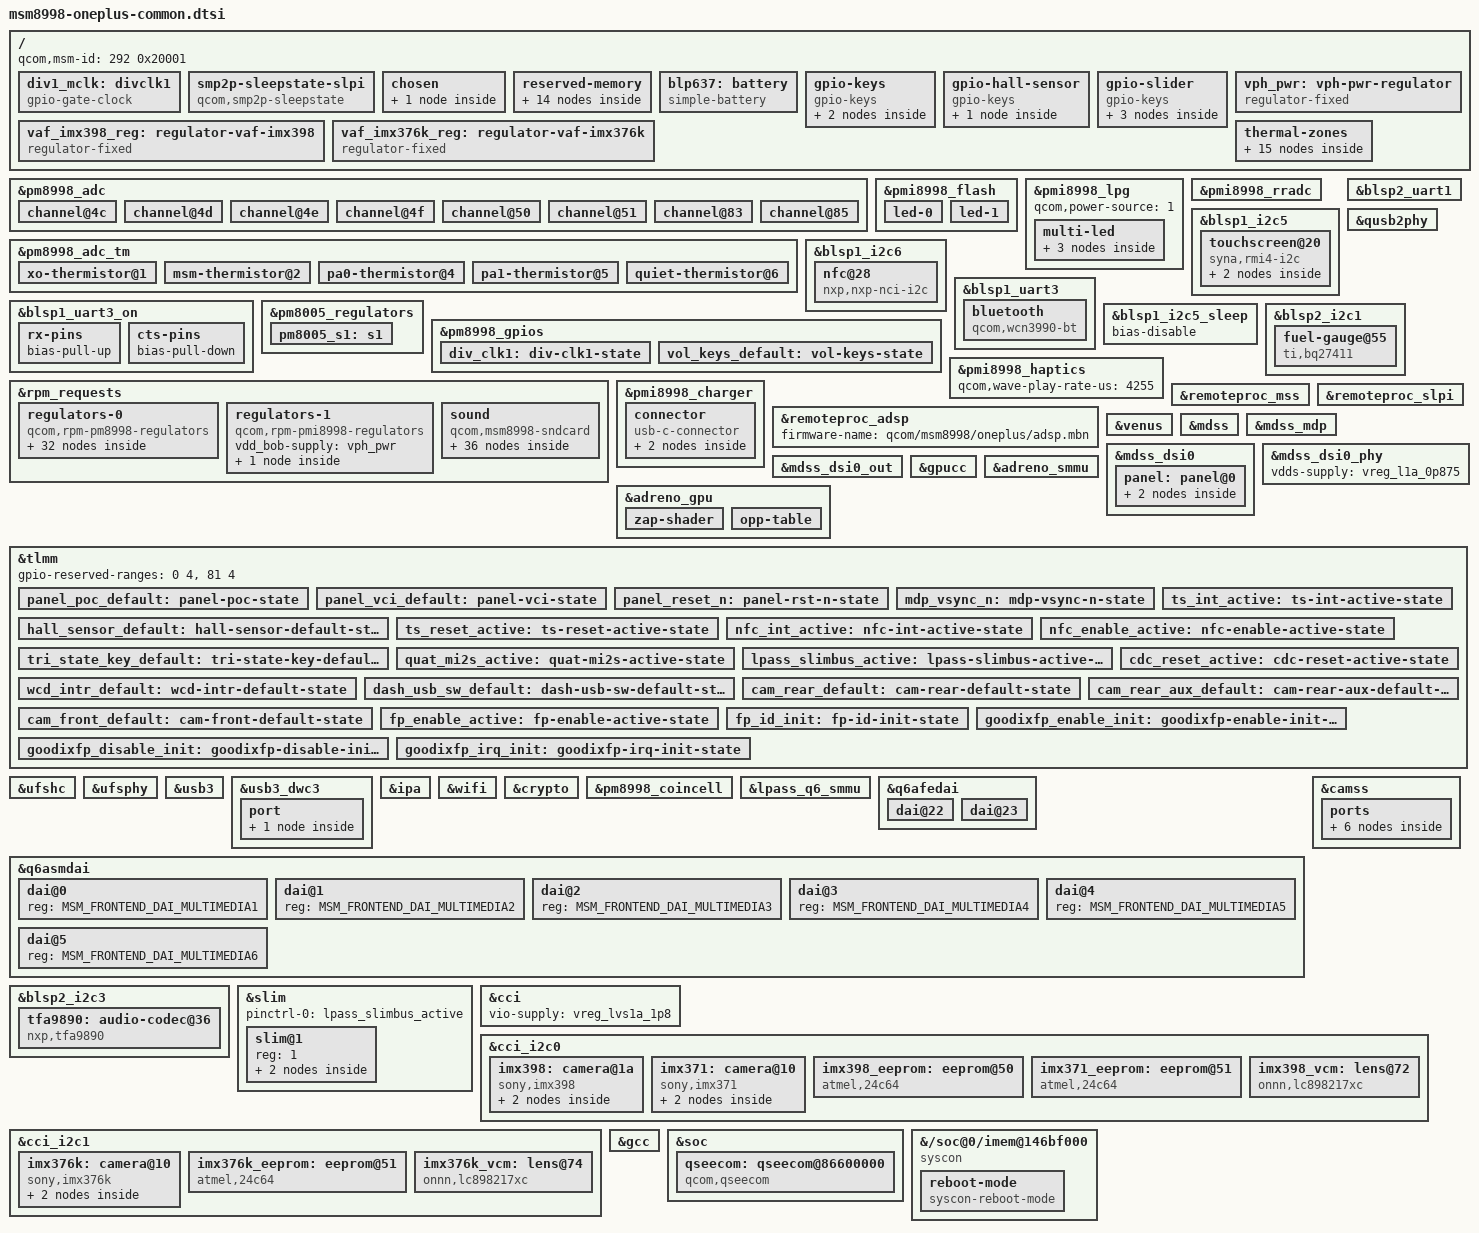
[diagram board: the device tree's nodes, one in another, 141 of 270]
// SPDX-License-Identifier: BSD-3-Clause
/*
 * OnePlus 5(T) (cheeseburger / dumpling) common device tree source based on msm8998-mtp.dtsi
 *
 * Copyright (c) 2021, Jami Kettunen <jamipkettunen@gmail.com>
 * Copyright (c) 2016, The Linux Foundation. All rights reserved.
 */

/dts-v1/;

#include <dt-bindings/gpio/gpio.h>
#include <dt-bindings/iio/qcom,spmi-vadc.h>
#include <dt-bindings/input/linux-event-codes.h>
#include <dt-bindings/leds/common.h>
#include <dt-bindings/pinctrl/qcom,pmic-gpio.h>
#include <dt-bindings/sound/qcom,q6afe.h>
#include <dt-bindings/sound/qcom,q6asm.h>
#include <dt-bindings/sound/qcom,wcd9335.h>
#include <dt-bindings/thermal/thermal.h>
#include "msm8998.dtsi"
#include "pm8005.dtsi"
#include "pm8998.dtsi"
#include "pmi8998.dtsi"

/*
 * Delete following upstream (msm8998.dtsi) reserved
 * memory mappings which are different in this device.
 */
/delete-node/ &adsp_mem;
/delete-node/ &mpss_mem;
/delete-node/ &venus_mem;
/delete-node/ &mba_mem;
/delete-node/ &slpi_mem;
/delete-node/ &ipa_fw_mem;
/delete-node/ &ipa_gsi_mem;
/delete-node/ &gpu_mem;
/delete-node/ &wlan_msa_mem;

/ {
	/* Required for bootloader to select correct board */
	qcom,msm-id = <292 0x20001>; /* 8998 v2.1 */

	div1_mclk: divclk1 {
		compatible = "gpio-gate-clock";
		pinctrl-names = "default";
		pinctrl-0 = <&div_clk1>;
		clocks = <&rpmcc RPM_SMD_DIV_CLK1>;
		#clock-cells = <0>;
		enable-gpios = <&pm8998_gpios 13 GPIO_ACTIVE_HIGH>;
	};

	smp2p-sleepstate-slpi {
		compatible = "qcom,smp2p-sleepstate";
		qcom,smem-states = <&slpi_smp2p_sleepstate 12>;
		qcom,smem-state-names = "sleepstate";
	};

	chosen {
		#address-cells = <2>;
		#size-cells = <2>;
		ranges;

		/* Use display framebuffer setup by the UEFI XBL bootloader for simplefb */
		framebuffer0: framebuffer@9d400000 {
			compatible = "simple-framebuffer";
			reg = <0x0 0x9d400000 0x0 0x2400000>;
			width = <1080>;
			height = <1920>;
			stride = <(1080 * 4)>;
			format = "a8r8g8b8";
			/*
			* That's a lot of clocks, but it's necessary due
			* to unused clk cleanup & no panel driver yet..
			*/
			clocks = <&mmcc MDSS_AHB_CLK>,
				 <&mmcc MDSS_AXI_CLK>,
				 <&mmcc MDSS_VSYNC_CLK>,
				 <&mmcc MDSS_MDP_CLK>,
				 <&mmcc MDSS_BYTE0_CLK>,
				 <&mmcc MDSS_BYTE0_INTF_CLK>,
				 <&mmcc MDSS_PCLK0_CLK>,
				 <&mmcc MDSS_ESC0_CLK>;
			power-domains = <&mmcc MDSS_GDSC>;
			status = "disabled";
		};
	};

	reserved-memory {
		/*
		 * OnePlus ADSP firmware requires 30 MiB in total, so increase the adsp_mem
		 * region by 4 MiB to account for this while relocating the other now
		 * conflicting memory nodes accordingly.
		 */
		adsp_mem: memory@8b200000 {
			reg = <0x0 0x8b200000 0x0 0x1e00000>;
			no-map;
		};

		mpss_mem: memory@8d000000 {
			reg = <0x0 0x8d000000 0x0 0x7000000>;
			no-map;
		};

		venus_mem: memory@94000000 {
			reg = <0x0 0x94000000 0x0 0x500000>;
			no-map;
		};

		mba_mem: memory@94500000 {
			reg = <0x0 0x94500000 0x0 0x200000>;
			no-map;
		};

		slpi_mem: memory@94700000 {
			reg = <0x0 0x94700000 0x0 0xf00000>;
			no-map;
		};

		ipa_fw_mem: memory@95600000 {
			reg = <0x0 0x95600000 0x0 0x10000>;
			no-map;
		};

		ipa_gsi_mem: memory@95610000 {
			reg = <0x0 0x95610000 0x0 0x5000>;
			no-map;
		};

		gpu_mem: memory@95615000 {
			reg = <0x0 0x95615000 0x0 0x100000>;
			no-map;
		};

		wlan_msa_mem: memory@95715000 {
			reg = <0x0 0x95715000 0x0 0x100000>;
			no-map;
		};
		/* Bootloader display framebuffer region */
		cont_splash_mem: memory@9d400000 {
			reg = <0x0 0x9d400000 0x0 0x2400000>;
			no-map;
		};

		/* For getting crash logs using Android downstream kernels */
		ramoops@ac000000 {
			compatible = "ramoops";
			reg = <0x0 0xac000000 0x0 0x200000>;
			console-size = <0x80000>;
			pmsg-size = <0x40000>;
			record-size = <0x8000>;
			ftrace-size = <0x20000>;
		};

		/*
		 * The following memory regions on downstream are "dynamically allocated"
		 * but given the same addresses every time. Hard code them as these addresses
		 * are where the OnePlus signed firmware expects them to be.
		 */
		ipa_fws_region: ipa@f6800000 {
			compatible = "shared-dma-pool";
			reg = <0x0 0xf6800000 0x0 0x5000>;
			no-map;
		};
		zap_shader_region: gpu@f6900000 {
			compatible = "shared-dma-pool";
			reg = <0x0 0xf6900000 0x0 0x2000>;
			no-map;
		};

		qseecom_region: qseecom-region {
			compatible = "shared-dma-pool";
			alloc-ranges = <0x0 0x0 0x0 0xffffffff>;
			reusable;
			alignment = <0x0 0x400000>;
			size = <0x0 0x2000000>;
			linux,cma-default;
		};
	};

	blp637: battery {
		compatible = "simple-battery";

		charge-full-design-microamp-hours = <3300000>;
		voltage-max-design-microvolt = <4370000>;
		voltage-min-design-microvolt = <3700000>;
		energy-full-design-microwatt-hours = <12700000>;
	};

	gpio-keys {
		compatible = "gpio-keys";
		label = "Volume buttons";
		autorepeat;

		pinctrl-names = "default";
		pinctrl-0 = <&vol_keys_default>;

		button-vol-down {
			label = "Volume down";
			gpios = <&pm8998_gpios 5 GPIO_ACTIVE_LOW>;
			linux,code = <KEY_VOLUMEDOWN>;
			debounce-interval = <15>;
			wakeup-source;
		};

		button-vol-up {
			label = "Volume up";
			gpios = <&pm8998_gpios 6 GPIO_ACTIVE_LOW>;
			linux,code = <KEY_VOLUMEUP>;
			debounce-interval = <15>;
			wakeup-source;
		};
	};

	gpio-hall-sensor {
		compatible = "gpio-keys";
		label = "Hall effect sensor";

		pinctrl-names = "default";
		pinctrl-0 = <&hall_sensor_default>;

		event-hall-sensor {
			label = "Hall Effect Sensor";
			gpios = <&tlmm 124 GPIO_ACTIVE_LOW>;
			linux,input-type = <EV_SW>;
			linux,code = <SW_LID>;
			linux,can-disable;
			wakeup-source;
		};
	};

	gpio-slider {
		compatible = "gpio-keys";
		label = "Tri-state key";

		pinctrl-names = "default";
		pinctrl-0 = <&tri_state_key_default>;

		key-mute {
			label = "Alert slider top";
			gpios = <&tlmm 40 GPIO_ACTIVE_LOW>;
			linux,code = <KEY_F1>;
			debounce-interval = <15>;
		};

		key-dnd {
			label = "Alert slider middle";
			gpios = <&tlmm 42 GPIO_ACTIVE_LOW>;
			linux,code = <KEY_F2>;
			debounce-interval = <15>;
		};

		key-normal {
			label = "Alert slider bottom";
			gpios = <&tlmm 26 GPIO_ACTIVE_LOW>;
			linux,code = <KEY_F3>;
			debounce-interval = <15>;
		};
	};

	vph_pwr: vph-pwr-regulator {
		compatible = "regulator-fixed";
		regulator-name = "vph_pwr";
		regulator-always-on;
		regulator-boot-on;
	};

	vaf_imx398_reg: regulator-vaf-imx398 {
		compatible = "regulator-fixed";
		regulator-name = "vaf_imx398";
		regulator-min-microvolt = <2850000>;
		regulator-max-microvolt = <2850000>;
		gpio = <&tlmm 6 GPIO_ACTIVE_HIGH>;
		enable-active-high;
		vin-supply = <&vreg_l22a_2p85>;
	};

	vaf_imx376k_reg: regulator-vaf-imx376k {
		compatible = "regulator-fixed";
		regulator-name = "vaf_imx376k";
		regulator-min-microvolt = <3300000>;
		regulator-max-microvolt = <3300000>;
		gpio = <&tlmm 77 GPIO_ACTIVE_HIGH>;
		enable-active-high;
		vin-supply = <&vreg_bob>;
	};

	thermal-zones {
		xo-thermal {
			thermal-sensors = <&pm8998_adc_tm 1>;

			trips {
				tr_xo_alert0: trip-point {
					temperature = <125000>;
					hysteresis = <10000>;
					type = "passive";
				};
			};
		};

		msm-thermal {
			thermal-sensors = <&pm8998_adc_tm 2>;

			trips {
				tr_msm_alert0: trip-point {
					temperature = <125000>;
					hysteresis = <10000>;
					type = "passive";
				};
			};
		};

		pa0-thermal {
			thermal-sensors = <&pm8998_adc_tm 4>;

			trips {
				tr_pa0_alert0: trip-point {
					temperature = <125000>;
					hysteresis = <10000>;
					type = "passive";
				};
			};
		};

		pa1-thermal {
			thermal-sensors = <&pm8998_adc_tm 5>;

			trips {
				tr_pa1_alert0: trip-point {
					temperature = <125000>;
					hysteresis = <10000>;
					type = "passive";
				};
			};
		};

		quiet-thermal {
			thermal-sensors = <&pm8998_adc_tm 6>;

			trips {
				tr_quiet_alert0: trip-point {
					temperature = <125000>;
					hysteresis = <10000>;
					type = "passive";
				};
			};
		};
	};
};

&pm8998_adc {
	channel@4c {
		reg = <ADC5_XO_THERM_100K_PU>;
		label = "xo_therm";
		qcom,ratiometric;
		qcom,hw-settle-time = <200>;
	};

	channel@4d {
		reg = <ADC5_AMUX_THM1_100K_PU>;
		label = "msm_therm";
		qcom,ratiometric;
		qcom,hw-settle-time = <200>;
	};

	channel@4e {
		reg = <ADC5_AMUX_THM2_100K_PU>;
		label = "ufs_therm";
		qcom,ratiometric;
		qcom,hw-settle-time = <200>;
	};

	channel@4f {
		reg = <ADC5_AMUX_THM3_100K_PU>;
		label = "pa_therm0";
		qcom,ratiometric;
		qcom,hw-settle-time = <200>;
	};

	channel@50 {
		reg = <ADC5_AMUX_THM4_100K_PU>;
		label = "pa_therm1";
		qcom,ratiometric;
		qcom,hw-settle-time = <200>;
	};

	channel@51 {
		reg = <ADC5_AMUX_THM5_100K_PU>;
		label = "quiet_therm";
		qcom,ratiometric;
		qcom,hw-settle-time = <200>;
	};

	channel@83 {
		reg = <ADC5_VPH_PWR>;
		label = "vph_pwr";
		qcom,decimation = <1024>;
		qcom,pre-scaling = <1 3>;
	};

	channel@85 {
		reg = <ADC5_VCOIN>;
		label = "vcoin";
		qcom,decimation = <1024>;
		qcom,pre-scaling = <1 3>;
	};
};

&pm8998_adc_tm {
	status = "okay";

	xo-thermistor@1 {
		reg = <1>;
		io-channels = <&pm8998_adc ADC5_XO_THERM_100K_PU>;
		qcom,ratiometric;
		qcom,hw-settle-time-us = <200>;
	};

	msm-thermistor@2 {
		reg = <2>;
		io-channels = <&pm8998_adc ADC5_AMUX_THM1_100K_PU>;
		qcom,ratiometric;
		qcom,hw-settle-time-us = <200>;
	};

	pa0-thermistor@4 {
		reg = <4>;
		io-channels = <&pm8998_adc ADC5_AMUX_THM3_100K_PU>;
		qcom,ratiometric;
		qcom,hw-settle-time-us = <200>;
	};

	pa1-thermistor@5 {
		reg = <5>;
		io-channels = <&pm8998_adc ADC5_AMUX_THM4_100K_PU>;
		qcom,ratiometric;
		qcom,hw-settle-time-us = <200>;
	};

	quiet-thermistor@6 {
		reg = <6>;
		io-channels = <&pm8998_adc ADC5_AMUX_THM5_100K_PU>;
		qcom,ratiometric;
		qcom,hw-settle-time-us = <200>;
	};
};

&pmi8998_flash {
	status = "okay";

	led-0 {
		function = LED_FUNCTION_FLASH;
		color = <LED_COLOR_ID_WHITE>;
		led-sources = <1>;
		led-max-microamp = <500000>;
		flash-max-microamp = <1500000>;
		flash-max-timeout-us = <1280000>;
	};

	led-1 {
		function = LED_FUNCTION_FLASH;
		color = <LED_COLOR_ID_YELLOW>;
		led-sources = <2>;
		led-max-microamp = <500000>;
		flash-max-microamp = <1500000>;
		flash-max-timeout-us = <1280000>;
	};
};

&pmi8998_lpg {
	qcom,power-source = <1>;
	status = "okay";

	multi-led {
		color = <LED_COLOR_ID_RGB>;
		function = LED_FUNCTION_STATUS;

		#address-cells = <1>;
		#size-cells = <0>;

		led@3 {
			reg = <3>;
			color = <LED_COLOR_ID_BLUE>;
		};

		led@4 {
			reg = <4>;
			color = <LED_COLOR_ID_GREEN>;
		};

		led@5 {
			reg = <5>;
			color = <LED_COLOR_ID_RED>;
		};
	};
};

&pmi8998_rradc {
	status = "okay";
};

&blsp1_i2c5 {
	status = "okay";

	touchscreen@20 {
		compatible = "syna,rmi4-i2c";
		reg = <0x20>;
		#address-cells = <1>;
		#size-cells = <0>;

		interrupt-parent = <&tlmm>;
		interrupts = <125 IRQ_TYPE_LEVEL_LOW>;
		wakeup-source;

		pinctrl-names = "default";
		pinctrl-0 = <&ts_int_active &ts_reset_active>;

		vdd-supply = <&vreg_l28_3p0>;
		vio-supply = <&vreg_l6a_1p8>;

		syna,reset-delay-ms = <20>;
		syna,startup-delay-ms = <20>;

		rmi4-f01@1 {
			reg = <0x01>;
			syna,nosleep-mode = <1>;
			syna,doze-interval-ms = <20>;
			syna,wakeup-doze;
		};

		rmi4_f12: rmi4-f12@12 {
			reg = <0x12>;
			syna,rezero-wait-ms = <20>;
			syna,sensor-type = <1>;
			touchscreen-x-mm = <68>;
			touchscreen-y-mm = <122>;
		};
	};
};

&blsp1_i2c6 {
	status = "okay";

	nfc@28 {
		compatible = "nxp,nxp-nci-i2c";
		reg = <0x28>;

		interrupt-parent = <&tlmm>;
		interrupts = <92 IRQ_TYPE_LEVEL_HIGH>;

		enable-gpios = <&tlmm 12 GPIO_ACTIVE_HIGH>;
		firmware-gpios = <&tlmm 93 GPIO_ACTIVE_HIGH>;

		pinctrl-names = "default";
		pinctrl-0 = <&nfc_int_active &nfc_enable_active>;
	};
};

&blsp1_uart3 {
	status = "okay";

	bluetooth {
		compatible = "qcom,wcn3990-bt";

		vddio-supply = <&vreg_s4a_1p8>;
		vddxo-supply = <&vreg_l7a_1p8>;
		vddrf-supply = <&vreg_l17a_1p3>;
		vddch0-supply = <&vreg_l25a_3p3>;
		max-speed = <3200000>;
	};
};

&blsp1_uart3_on {
	rx-pins {
		/delete-property/ bias-disable;
		/*
		 * Configure a pull-up on 46 (RX). This is needed to
		 * avoid garbage data when the TX pin of the Bluetooth
		 * module is in tri-state (module powered off or not
		 * driving the signal yet).
		 */
		bias-pull-up;
	};

	cts-pins {
		/delete-property/ bias-disable;
		/*
		 * Configure a pull-down on 47 (CTS) to match the pull
		 * of the Bluetooth module.
		 */
		bias-pull-down;
	};
};

&blsp2_uart1 {
	status = "okay";
};

&pm8005_regulators {
	/* VDD_GFX supply */
	pm8005_s1: s1 {
		regulator-min-microvolt = <524000>;
		regulator-max-microvolt = <1100000>;
		regulator-enable-ramp-delay = <500>;
		/* Hack until we rig up the gpu consumer */
		regulator-always-on;
	};
};

&pm8998_gpios {
	div_clk1: div-clk1-state {
		pins = "gpio13";
		function = "func2";
		power-source = <0>;
	};

	vol_keys_default: vol-keys-state {
		pins = "gpio5", "gpio6";
		function = "normal";
		bias-pull-up;
		input-enable;
		qcom,drive-strength = <PMIC_GPIO_STRENGTH_NO>;
	};
};

&qusb2phy {
	status = "okay";

	vdd-supply = <&vreg_l1a_0p875>;
	vdda-pll-supply = <&vreg_l12a_1p8>;
	vdda-phy-dpdm-supply = <&vreg_l24a_3p075>;
};

&rpm_requests {
	regulators-0 {
		compatible = "qcom,rpm-pm8998-regulators";

		vdd_s1-supply = <&vph_pwr>;
		vdd_s2-supply = <&vph_pwr>;
		vdd_s3-supply = <&vph_pwr>;
		vdd_s4-supply = <&vph_pwr>;
		vdd_s5-supply = <&vph_pwr>;
		vdd_s6-supply = <&vph_pwr>;
		vdd_s7-supply = <&vph_pwr>;
		vdd_s8-supply = <&vph_pwr>;
		vdd_s9-supply = <&vph_pwr>;
		vdd_s10-supply = <&vph_pwr>;
		vdd_s11-supply = <&vph_pwr>;
		vdd_s12-supply = <&vph_pwr>;
		vdd_s13-supply = <&vph_pwr>;
		vdd_l1_l27-supply = <&vreg_s7a_1p025>;
		vdd_l2_l8_l17-supply = <&vreg_s3a_1p35>;
		vdd_l3_l11-supply = <&vreg_s7a_1p025>;
		vdd_l4_l5-supply = <&vreg_s7a_1p025>;
		vdd_l6-supply = <&vreg_s5a_2p04>;
		vdd_l7_l12_l14_l15-supply = <&vreg_s5a_2p04>;
		vdd_l9-supply = <&vreg_bob>;
		vdd_l10_l23_l25-supply = <&vreg_bob>;
		vdd_l13_l19_l21-supply = <&vreg_bob>;
		vdd_l16_l28-supply = <&vreg_bob>;
		vdd_l18_l22-supply = <&vreg_bob>;
		vdd_l20_l24-supply = <&vreg_bob>;
		vdd_l26-supply = <&vreg_s3a_1p35>;
		vdd_lvs1_lvs2-supply = <&vreg_s4a_1p8>;

		vreg_s3a_1p35: s3 {
			regulator-min-microvolt = <1352000>;
			regulator-max-microvolt = <1352000>;
		};

		vreg_s4a_1p8: s4 {
			regulator-min-microvolt = <1800000>;
			regulator-max-microvolt = <1800000>;
			regulator-allow-set-load;
		};

		vreg_s5a_2p04: s5 {
			regulator-min-microvolt = <1904000>;
			regulator-max-microvolt = <2040000>;
		};

		vreg_s7a_1p025: s7 {
			regulator-min-microvolt = <900000>;
			regulator-max-microvolt = <1028000>;
		};

		vreg_l1a_0p875: l1 {
			regulator-min-microvolt = <880000>;
			regulator-max-microvolt = <880000>;
		};

		vreg_l2a_1p2: l2 {
			regulator-min-microvolt = <1200000>;
			regulator-max-microvolt = <1200000>;
		};

		vreg_l3a_1p0: l3 {
			regulator-min-microvolt = <1000000>;
			regulator-max-microvolt = <1000000>;
		};

		vreg_l5a_0p8: l5 {
			regulator-min-microvolt = <800000>;
			regulator-max-microvolt = <800000>;
		};

		vreg_l6a_1p8: l6 {
			regulator-min-microvolt = <1808000>;
			regulator-max-microvolt = <1808000>;
		};

		vreg_l7a_1p8: l7 {
			regulator-min-microvolt = <1800000>;
			regulator-max-microvolt = <1800000>;
		};

		vreg_l8a_1p2: l8 {
			regulator-min-microvolt = <1200000>;
			regulator-max-microvolt = <1200000>;
		};

		vreg_l9a_1p8: l9 {
			regulator-min-microvolt = <1808000>;
			regulator-max-microvolt = <2960000>;
		};

		vreg_l10a_1p8: l10 {
			regulator-min-microvolt = <1808000>;
			regulator-max-microvolt = <2960000>;
		};

		vreg_l11a_1p0: l11 {
			regulator-min-microvolt = <1000000>;
			regulator-max-microvolt = <1000000>;
		};

		vreg_l12a_1p8: l12 {
			regulator-min-microvolt = <1800000>;
			regulator-max-microvolt = <1800000>;
		};

		vreg_l13a_2p95: l13 {
			regulator-min-microvolt = <1808000>;
			regulator-max-microvolt = <2960000>;
		};

		vreg_l14a_1p88: l14 {
			regulator-min-microvolt = <1880000>;
			regulator-max-microvolt = <1880000>;
		};

		vreg_l15a_1p8: l15 {
			regulator-min-microvolt = <1800000>;
			regulator-max-microvolt = <1800000>;
		};

		vreg_l16a_2p7: l16 {
			regulator-min-microvolt = <2704000>;
			regulator-max-microvolt = <2704000>;
		};

		vreg_l17a_1p3: l17 {
			regulator-min-microvolt = <1304000>;
			regulator-max-microvolt = <1304000>;
		};

		vreg_l18a_2p7: l18 {
			regulator-min-microvolt = <2704000>;
			regulator-max-microvolt = <2704000>;
		};

		vreg_l19a_3p0: l19 {
			regulator-min-microvolt = <3008000>;
			regulator-max-microvolt = <3008000>;
		};

		vreg_l20a_2p95: l20 {
			regulator-min-microvolt = <2960000>;
			regulator-max-microvolt = <2960000>;
			regulator-allow-set-load;
		};
		vreg_l21a_2p95: l21 {
			regulator-min-microvolt = <2960000>;
			regulator-max-microvolt = <2960000>;
			regulator-system-load = <800000>;
			regulator-allow-set-load;
		};

		vreg_l22a_2p85: l22 {
			regulator-min-microvolt = <2864000>;
			regulator-max-microvolt = <2864000>;
		};

		vreg_l23a_3p3: l23 {
			regulator-min-microvolt = <3312000>;
			regulator-max-microvolt = <3312000>;
		};

		vreg_l24a_3p075: l24 {
			regulator-min-microvolt = <3088000>;
			regulator-max-microvolt = <3088000>;
		};

		vreg_l25a_3p3: l25 {
			regulator-min-microvolt = <3104000>;
			regulator-max-microvolt = <3312000>;
		};

		vreg_l26a_1p2: l26 {
			regulator-min-microvolt = <1200000>;
			regulator-max-microvolt = <1200000>;
			regulator-allow-set-load;
		};

		vreg_l28_3p0: l28 {
			regulator-min-microvolt = <3008000>;
			regulator-max-microvolt = <3008000>;
		};

		vreg_lvs1a_1p8: lvs1 { };
		vreg_lvs2a_1p8: lvs2 { };
	};

	regulators-1 {
		compatible = "qcom,rpm-pmi8998-regulators";

		vdd_bob-supply = <&vph_pwr>;

		vreg_bob: bob {
			regulator-min-microvolt = <3312000>;
			regulator-max-microvolt = <3600000>;
		};
	};

	sound {
		compatible = "qcom,msm8998-sndcard";
		model = "OnePlus 5T";
		pinctrl-names = "default";
		pinctrl-0 = <&quat_mi2s_active>;

		audio-routing = "RX_BIAS", "MCLK",
				"AMIC2", "MIC BIAS2",
				"AMIC3", "MIC BIAS2",
				"AMIC4", "MIC BIAS2",
				"AMIC5", "MIC BIAS3",
				"Speaker", "Spkr OUT";

		mm1-dai-link {
			link-name = "MultiMedia1";
			cpu {
				sound-dai = <&q6asmdai MSM_FRONTEND_DAI_MULTIMEDIA1>;
			};
		};

		mm2-dai-link {
			link-name = "MultiMedia2";
			cpu {
				sound-dai = <&q6asmdai MSM_FRONTEND_DAI_MULTIMEDIA2>;
			};
		};

		mm3-dai-link {
			link-name = "MultiMedia3";
			cpu {
				sound-dai = <&q6asmdai MSM_FRONTEND_DAI_MULTIMEDIA3>;
			};
		};

		mm4-dai-link {
			link-name = "MultiMedia4";
			cpu {
				sound-dai = <&q6asmdai MSM_FRONTEND_DAI_MULTIMEDIA4>;
			};
		};

		mm5-dai-link {
			link-name = "MultiMedia5";
			cpu {
				sound-dai = <&q6asmdai MSM_FRONTEND_DAI_MULTIMEDIA5>;
			};
		};

		mm6-dai-link {
			link-name = "MultiMedia6";
			cpu {
				sound-dai = <&q6asmdai MSM_FRONTEND_DAI_MULTIMEDIA6>;
			};
		};

		speaker-dai-link {
			link-name = "Speaker Playback";
			cpu {
				sound-dai = <&q6afedai QUATERNARY_MI2S_RX>;
			};

			platform {
				sound-dai = <&q6routing>;
			};

			codec {
				sound-dai = <&tfa9890>;
			};
		};

		slim-dai-link {
			link-name = "SLIM Playback 1";
			cpu {
				sound-dai = <&q6afedai SLIMBUS_0_RX>;
			};

			platform {
				sound-dai = <&q6routing>;
			};

			codec {
				sound-dai = <&wcd9335 AIF1_PB>;
			};
		};

		slimcap-dai-link {
			link-name = "SLIM Capture 1";
			cpu {
				sound-dai = <&q6afedai SLIMBUS_0_TX>;
			};

			platform {
				sound-dai = <&q6routing>;
			};

			codec {
				sound-dai = <&wcd9335 AIF1_CAP>;
			};
		};

		slim2-dai-link {
			link-name = "SLIM Playback 2";
			cpu {
				sound-dai = <&q6afedai SLIMBUS_1_RX>;
			};

			platform {
				sound-dai = <&q6routing>;
			};

			codec {
				sound-dai = <&wcd9335 AIF2_PB>;
			};
		};

		slimcap2-dai-link {
			link-name = "SLIM Capture 2";
			cpu {
				sound-dai = <&q6afedai SLIMBUS_1_TX>;
			};

			platform {
				sound-dai = <&q6routing>;
			};

			codec {
				sound-dai = <&wcd9335 AIF2_CAP>;
			};
		};

		slimcap3-dai-link {
			link-name = "SLIM Capture 3";
			cpu {
				sound-dai = <&q6afedai SLIMBUS_2_TX>;
			};

			platform {
				sound-dai = <&q6routing>;
			};

			codec {
				sound-dai = <&wcd9335 AIF3_CAP>;
			};
		};
	};

};

&blsp1_i2c5_sleep {
	/delete-property/ bias-pull-up;
	/* Configure a no-pull on TP I2C sleep to match downstream. */
	bias-disable;
};

&blsp2_i2c1 {
	status = "okay";

	fuel-gauge@55 {
		compatible = "ti,bq27411";
		reg = <0x55>;

		monitored-battery = <&blp637>;
	};
};

&pmi8998_haptics {
	status = "okay";

	qcom,wave-play-rate-us = <4255>;
};

&pmi8998_charger {
	status = "okay";

	interrupts = <0x2 0x13 0x4 IRQ_TYPE_EDGE_BOTH>,
		     <0x2 0x12 0x2 IRQ_TYPE_EDGE_BOTH>,
		     <0x2 0x16 0x1 IRQ_TYPE_EDGE_RISING>,
		     <0x2 0x13 0x6 IRQ_TYPE_EDGE_RISING>,
		     <0x2 0x13 0x7 IRQ_TYPE_EDGE_RISING>,
		     <0x2 0x11 0x1 IRQ_TYPE_EDGE_BOTH>;
	interrupt-names = "usb-plugin",
			  "bat-ov",
			  "wdog-bark",
			  "usbin-icl-change",
			  "type-c-change",
			  "otg-overcurrent";

	monitored-battery = <&blp637>;

	connector {
		compatible = "usb-c-connector";
		label = "USB-C";
		power-role = "dual";
		data-role = "dual";
		try-power-role = "sink";
		typec-power-opmode = "1.5A";

		port {
			pmi8998_typec_hs: endpoint {
				remote-endpoint = <&usb3_dwc3_hs>;
			};
		};
	};
};

&remoteproc_adsp {
	status = "okay";

	firmware-name = "qcom/msm8998/oneplus/adsp.mbn";
};

&remoteproc_mss {
	status = "okay";

	firmware-name = "qcom/msm8998/oneplus/mba.mbn", "qcom/msm8998/oneplus/modem.mbn";
};

&remoteproc_slpi {
	status = "okay";

	firmware-name = "qcom/msm8998/oneplus/slpi_v2.mbn";
};

&venus {
	status = "okay";

	power-domains = <&mmcc VIDEO_TOP_GDSC>,
			<&mmcc BIMC_SMMU_GDSC>,
			<&mmcc VIDEO_SUBCORE0_GDSC>,
			<&mmcc VIDEO_SUBCORE1_GDSC>;
	power-domain-names = "venus", "smmu", "vcodec0", "vcodec1";

	clocks = <&mmcc VIDEO_CORE_CLK>,
		 <&mmcc VIDEO_AHB_CLK>,
		 <&mmcc VIDEO_AXI_CLK>,
		 <&mmcc VIDEO_MAXI_CLK>,
		 <&gcc GCC_MMSS_SYS_NOC_AXI_CLK>,
		 <&mmcc MNOC_AHB_CLK>,
		 <&mmcc MNOC_MAXI_CLK>,
		 <&mmcc BIMC_SMMU_AHB_CLK>,
		 <&mmcc BIMC_SMMU_AXI_CLK>,
		 <&mmcc VIDEO_SUBCORE0_CLK>,
		 <&mmcc VIDEO_SUBCORE1_CLK>;
	clock-names = "core", "iface", "bus", "mbus",
		      "noc_axi", "mnoc_ahb",
		      "mnoc_maxi", "smmu_ahb", "smmu_axi",
		      "subcore0", "subcore1";

	firmware-name = "qcom/msm8998/oneplus/venus.mbn";
};

&mdss {
	status = "okay";
};

&mdss_mdp {
	status = "okay";
};

&mdss_dsi0 {
	#address-cells = <1>;
	#size-cells = <0>;
	status = "okay";

	vdd-supply = <&vreg_l1a_0p875>;
	vdda-supply = <&vreg_l2a_1p2>;

	panel: panel@0 {
		reg = <0>;

		poc-gpios = <&tlmm 66 GPIO_ACTIVE_HIGH>;
		vci-gpios = <&tlmm 21 GPIO_ACTIVE_HIGH>;
		reset-gpios = <&tlmm 94 GPIO_ACTIVE_LOW>;

		vddio-supply = <&vreg_l14a_1p88>;

		pinctrl-names = "default";
		pinctrl-0 = <&panel_reset_n &panel_poc_default &panel_vci_default &mdp_vsync_n>;

		port {
			panel_in: endpoint {
				remote-endpoint = <&mdss_dsi0_out>;
			};
		};
	};
};

&mdss_dsi0_phy {
	status = "okay";
	vdds-supply = <&vreg_l1a_0p875>;
};

&mdss_dsi0_out {
	remote-endpoint = <&panel_in>;
	data-lanes = <0 1 2 3>;
};

/* Adreno 540 GPU */
&gpucc {
	status = "okay";
};

&gpu_mem {
	compatible = "shared-dma-pool";
};

&adreno_gpu {
	status = "okay";

	zap-shader {
		memory-region = <&zap_shader_region>;
		firmware-name = "qcom/msm8998/oneplus/a540_zap.mbn";
	};

	opp-table {
		/delete-node/ opp-710000097;
		/delete-node/ opp-670000048;
		/delete-node/ opp-596000097;
		/delete-node/ opp-515000097;
		/delete-node/ opp-414000000;
		/delete-node/ opp-342000000;
	};
};

&adreno_smmu {
	status = "okay";
};

&pm8005_s1 {
	regulator-min-microvolt = <988000>;
};

&tlmm {
	gpio-reserved-ranges = <0 4>, <81 4>;

	panel_poc_default: panel-poc-state {
		pins = "gpio66";
		function = "gpio";
		drive-strength = <8>;
		bias-disable;
	};

	panel_vci_default: panel-vci-state {
		pins = "gpio21";
		function = "gpio";
		drive-strength = <8>;
		bias-disable;
	};

	panel_reset_n: panel-rst-n-state {
		pins = "gpio94";
		function = "gpio";
		drive-strength = <8>;
		bias-disable;
	};

	mdp_vsync_n: mdp-vsync-n-state {
		pins = "gpio10";
		function = "mdp_vsync_a";
		drive-strength = <2>;
		bias-pull-down;
	};

	hall_sensor_default: hall-sensor-default-state {
		pins = "gpio124";
		function = "gpio";
		drive-strength = <2>;
		bias-disable;
	};

	ts_int_active: ts-int-active-state {
		pins = "gpio125";
		function = "gpio";
		drive-strength = <8>;
		bias-pull-up;
	};

	ts_reset_active: ts-reset-active-state {
		pins = "gpio89";
		function = "gpio";
		drive-strength = <8>;
		bias-pull-up;
	};

	nfc_int_active: nfc-int-active-state {
		pins = "gpio92";
		function = "gpio";
		drive-strength = <6>;
		bias-pull-up;
	};

	nfc_enable_active: nfc-enable-active-state {
		pins = "gpio12", "gpio93";
		function = "gpio";
		drive-strength = <6>;
		bias-disable;
	};

	tri_state_key_default: tri-state-key-default-state {
		pins = "gpio40", "gpio42", "gpio26";
		function = "gpio";
		drive-strength = <2>;
		bias-disable;
	};

	quat_mi2s_active: quat-mi2s-active-state {
		pins = "gpio58", "gpio59", "gpio60", "gpio61";
		function = "qua_mi2s";
		drive-strength = <8>;
		bias-disable;
	};

	lpass_slimbus_active: lpass-slimbus-active-state {
		pins = "gpio70", "gpio71", "gpio72";
		function = "lpass_slimbus";
		drive-strength = <8>;
		bias-disable;
	};

	cdc_reset_active: cdc-reset-active-state {
		pins = "gpio64";
		function = "gpio";
		drive-strength = <16>;
		bias-disable;
	};

	wcd_intr_default: wcd-intr-default-state {
		pins = "gpio54";
		function = "gpio";
		drive-strength = <2>;
		bias-pull-down;
	};

	/* Lock OnePlus Dash USB D+/D- analog switch permanently to MSM8998 PHY */
	dash_usb_sw_default: dash-usb-sw-default-state {
		pins = "gpio90", "gpio91", "gpio96";
		function = "gpio";
		drive-strength = <2>;
		bias-disable;
		output-low;
	};

	cam_rear_default: cam-rear-default-state {
		pins = "gpio6", "gpio7", "gpio27", "gpio30";
		function = "gpio";
		drive-strength = <2>;
		bias-disable;
	};

	cam_rear_aux_default: cam-rear-aux-default-state {
		pins = "gpio8", "gpio9", "gpio23", "gpio77";
		function = "gpio";
		drive-strength = <2>;
		bias-disable;
	};

	cam_front_default: cam-front-default-state {
		pins = "gpio28", "gpio78", "gpio85";
		function = "gpio";
		drive-strength = <2>;
		bias-disable;
	};

	fp_enable_active: fp-enable-active-state {
		pins = "gpio25";
		function = "gpio";
		drive-strength = <2>;
		bias-pull-up;
		output-high;
	};

	fp_id_init: fp-id-init-state {
		pins = "gpio39", "gpio41", "gpio63";
		function = "gpio";
		drive-strength = <2>;
		bias-disable;
		input-enable;
	};

	goodixfp_enable_init: goodixfp-enable-init-state {
		pins = "gpio65";
		function = "gpio";
		drive-strength = <8>;
		bias-pull-up;
		output-high;
	};

	goodixfp_disable_init: goodixfp-disable-init-state {
		pins = "gpio65";
		function = "gpio";
		drive-strength = <8>;
		bias-pull-up;
		output-low;
	};

	goodixfp_irq_init: goodixfp-irq-init-state {
		pins = "gpio121";
		function = "gpio";
		drive-strength = <2>;
		bias-disable;
		input-enable;
	};
};

&ufshc {
	status = "okay";

	vcc-supply = <&vreg_l20a_2p95>;
	vccq-supply = <&vreg_l26a_1p2>;
	vccq2-supply = <&vreg_s4a_1p8>;
	vdd-hba-supply = <&vreg_l26a_1p2>;
	vcc-max-microamp = <750000>;
	vccq-max-microamp = <560000>;
	vccq2-max-microamp = <750000>;
};

&ufsphy {
	status = "okay";

	vdda-phy-supply = <&vreg_l1a_0p875>;
	vdda-pll-supply = <&vreg_l2a_1p2>;
};

&usb3 {
	status = "okay";

	pinctrl-names = "default";
	pinctrl-0 = <&dash_usb_sw_default>;

	/* Disable USB3 clock requirement as the device only supports USB2 */
	qcom,select-utmi-as-pipe-clk;
};

&usb3_dwc3 {
	/* Drop the unused USB 3 PHY */
	phys = <&qusb2phy>;
	phy-names = "usb2-phy";

	/* Fastest mode for USB 2 */
	maximum-speed = "high-speed";

	dr_mode = "otg";
	usb-role-switch;
	role-switch-default-mode = "peripheral";

	port {
		usb3_dwc3_hs: endpoint {
			remote-endpoint = <&pmi8998_typec_hs>;
		};
	};
};

&ipa {
	status = "okay";

	qcom,gsi-loader = "self";
	memory-region = <&ipa_fws_region>;
	firmware-name = "qcom/msm8998/oneplus/ipa_fws.mbn";
};

&wifi {
	status = "okay";
	vdd-0.8-cx-mx-supply = <&vreg_l5a_0p8>;
	vdd-1.8-xo-supply = <&vreg_l7a_1p8>;
	vdd-1.3-rfa-supply = <&vreg_l17a_1p3>;
	vdd-3.3-ch0-supply = <&vreg_l25a_3p3>;
};

&crypto {
	status = "okay";
};

&pm8998_coincell {
	qcom,rset-ohms = <800>;
	qcom,vset-millivolts = <3200>;
	status = "okay";
};

&lpass_q6_smmu {
	status = "okay";
};

&q6afedai {
	dai@22 {
		reg = <QUATERNARY_MI2S_RX>;
		qcom,sd-lines = <1>;
	};

	dai@23 {
		reg = <QUATERNARY_MI2S_TX>;
		qcom,sd-lines = <0>;
	};
};

&q6asmdai {
	dai@0 {
		reg = <MSM_FRONTEND_DAI_MULTIMEDIA1>;
	};

	dai@1 {
		reg = <MSM_FRONTEND_DAI_MULTIMEDIA2>;
	};

	dai@2 {
		reg = <MSM_FRONTEND_DAI_MULTIMEDIA3>;
	};

	dai@3 {
		reg = <MSM_FRONTEND_DAI_MULTIMEDIA4>;
	};

	dai@4 {
		reg = <MSM_FRONTEND_DAI_MULTIMEDIA5>;
	};

	dai@5 {
		reg = <MSM_FRONTEND_DAI_MULTIMEDIA6>;
	};
};

&blsp2_i2c3 {
	status = "okay";

	tfa9890: audio-codec@36 {
		compatible = "nxp,tfa9890";
		reg = <0x36>;
		reset-gpios = <&tlmm 49 GPIO_ACTIVE_HIGH>;
		vddd-supply = <&vreg_s4a_1p8>;
		vddp-supply = <&vreg_bob>;
		sound-name-prefix = "Spkr";
		#sound-dai-cells = <0>;
	};
};

&slim {
	status = "okay";
	pinctrl-names = "default";
	pinctrl-0 = <&lpass_slimbus_active>;

	slim@1 {
		reg = <1>;
		#address-cells = <2>;
		#size-cells = <0>;

		tasha_ifd: ifd@0,0 {
			compatible = "slim217,1a0";
			reg = <0 0>;
		};

		wcd9335: codec@1,0 {
			compatible = "slim217,1a0";
			reg = <1 0>;
			slim-ifc-dev = <&tasha_ifd>;

			#sound-dai-cells = <1>;

			clock-names = "mclk", "slimbus";
			clocks = <&div1_mclk>,
				 <&rpmcc RPM_SMD_XO_CLK_SRC>;

			interrupt-parent = <&tlmm>;
			interrupts = <54 IRQ_TYPE_LEVEL_HIGH>;
			interrupt-names = "intr1";
			interrupt-controller;
			#interrupt-cells = <1>;

			pinctrl-names = "default";
			pinctrl-0 = <&cdc_reset_active &wcd_intr_default>;

			reset-gpios = <&tlmm 64 GPIO_ACTIVE_LOW>;

			vdd-buck-supply = <&vreg_s4a_1p8>;
			vdd-buck-sido-supply = <&vreg_s4a_1p8>;
			vdd-tx-supply = <&vreg_s4a_1p8>;
			vdd-rx-supply = <&vreg_s4a_1p8>;
			vdd-io-supply = <&vreg_s4a_1p8>;
		};
	};
};

&camss {
	status = "okay";

	vdda-supply = <&vreg_l2a_1p2>;
	vdd_sec-supply = <&vreg_l1a_0p875>;

	ports {
		port@0 {
			reg = <0>;
			csiphy0_ep: endpoint {
				data-lanes = <0 1 2 3>;
				remote-endpoint = <&imx398_ep>;
			};
		};

		port@1 {
			reg = <1>;
			csiphy1_ep: endpoint {
				data-lanes = <0 1 2 3>;
				remote-endpoint = <&imx376k_ep>;
			};
		};

		port@2 {
			reg = <2>;
			csiphy2_ep: endpoint {
				data-lanes = <0 1 2 3>;
				remote-endpoint = <&imx371_ep>;
			};
		};
	};
};

&cci {
	status = "okay";
	vio-supply = <&vreg_lvs1a_1p8>;
};

&cci_i2c0 {
	imx398: camera@1a {
		compatible = "sony,imx398";
		reg = <0x1a>;

		assigned-clocks = <&mmcc CAMSS_MCLK0_CLK>;
		assigned-clock-rates = <24000000>;
		clocks = <&mmcc CAMSS_MCLK0_CLK>;

		pinctrl-names = "default";
		pinctrl-0 = <&cam_mclk0_default &cam_rear_default>;

		reset-gpios = <&tlmm 30 GPIO_ACTIVE_LOW>;
		vdig-gpios = <&tlmm 7 GPIO_ACTIVE_HIGH>;
		vana-gpios = <&tlmm 27 GPIO_ACTIVE_HIGH>;

		vio-supply = <&vreg_lvs1a_1p8>;
		vana-supply = <&vreg_bob>;
		vdig-supply = <&vreg_s3a_1p35>;
		vaf-supply = <&vaf_imx398_reg>;

		lens-focus = <&imx398_vcm>;

		orientation = <1>;
		rotation = <90>;

		port {
			imx398_ep: endpoint {
				data-lanes = <0 1 2 3>;
				link-frequencies = /bits/ 64 <750000000 666000000 558000000 564000000 525000000>;
				remote-endpoint = <&csiphy0_ep>;
			};
		};
	};

	imx371: camera@10 {
		compatible = "sony,imx371";
		reg = <0x10>;

		assigned-clocks = <&mmcc CAMSS_MCLK1_CLK>;
		assigned-clock-rates = <24000000>;
		clocks = <&mmcc CAMSS_MCLK1_CLK>;

		pinctrl-names = "default";
		pinctrl-0 = <&cam_mclk1_default &cam_front_default>;

		reset-gpios = <&tlmm 28 GPIO_ACTIVE_LOW>;
		vdig-gpios = <&tlmm 78 GPIO_ACTIVE_HIGH>;
		vana-gpios = <&tlmm 85 GPIO_ACTIVE_HIGH>;

		vio-supply = <&vreg_lvs1a_1p8>;
		vana-supply = <&vreg_bob>;
		vdig-supply = <&vreg_s3a_1p35>;

		orientation = <0>;
		rotation = <270>;

		port {
			imx371_ep: endpoint {
				data-lanes = <0 1 2 3>;
				link-frequencies = /bits/ 64 <654000000 400000000>;
				remote-endpoint = <&csiphy2_ep>;
			};
		};
	};

	imx398_eeprom: eeprom@50 {
		compatible = "atmel,24c64";
		reg = <0x50>;
		pagesize = <32>;
		vcc-supply = <&vreg_lvs1a_1p8>;
		read-only;
	};

	imx371_eeprom: eeprom@51 {
		compatible = "atmel,24c64";
		reg = <0x51>;
		pagesize = <32>;
		vcc-supply = <&vreg_lvs1a_1p8>;
		read-only;
	};

	imx398_vcm: lens@72 {
		compatible = "onnn,lc898217xc";
		reg = <0x72>;
		vio-supply = <&vreg_lvs1a_1p8>;
		vaf-supply = <&vaf_imx398_reg>;
	};
};

&cci_i2c1 {
	imx376k: camera@10 {
		compatible = "sony,imx376k";
		reg = <0x10>;

		assigned-clocks = <&mmcc CAMSS_MCLK2_CLK>;
		assigned-clock-rates = <24000000>;
		clocks = <&mmcc CAMSS_MCLK2_CLK>;

		pinctrl-names = "default";
		pinctrl-0 = <&cam_mclk2_default &cam_rear_aux_default>;

		reset-gpios = <&tlmm 9 GPIO_ACTIVE_LOW>;
		vdig-gpios = <&tlmm 8 GPIO_ACTIVE_HIGH>;
		vana-gpios = <&tlmm 23 GPIO_ACTIVE_HIGH>;

		vio-supply = <&vreg_lvs1a_1p8>;
		vana-supply = <&vreg_bob>;
		vdig-supply = <&vreg_s3a_1p35>;
		vaf-supply = <&vaf_imx376k_reg>;

		lens-focus = <&imx376k_vcm>;

		orientation = <1>;
		rotation = <90>;

		port {
			imx376k_ep: endpoint {
				data-lanes = <0 1 2 3>;
				link-frequencies = /bits/ 64 <500000000>;
				remote-endpoint = <&csiphy1_ep>;
			};
		};
	};

	imx376k_eeprom: eeprom@51 {
		compatible = "atmel,24c64";
		reg = <0x51>;
		pagesize = <32>;
		vcc-supply = <&vreg_lvs1a_1p8>;
		read-only;
	};

	imx376k_vcm: lens@74 {
		compatible = "onnn,lc898217xc";
		reg = <0x74>;
		vio-supply = <&vreg_lvs1a_1p8>;
		vaf-supply = <&vaf_imx376k_reg>;
	};
};

/*
 * Protect GCC hardware clocks not managed or disabled by the stock MSM8998 HLOS
 * clock tree (including GCC_MSS_AT_CLK and CoreSight/QM/GPU clocks) so
 * clk_disable_unused() does not gate active remoteproc/MSS paths.
 */
&gcc {
	protected-clocks = <AGGRE2_SNOC_NORTH_AXI>,
			   <SSC_XO>,
			   <SSC_CNOC_AHBS_CLK>,
			   <GCC_MSS_AT_CLK>,
			   <GCC_AGGRE1_NOC_XO_CLK>,
			   <GCC_IM_SLEEP>,
			   <GCC_HMSS_AT_CLK>,
			   <GCC_MMSS_QM_AHB_CLK>,
			   <GCC_MMSS_QM_CORE_CLK>,
			   <GCC_GPU_BIMC_GFX_SRC_CLK>,
			   <GCC_GPU_SNOC_DVM_GFX_CLK>;
};


&soc {
	qseecom: qseecom@86600000 {
		compatible = "qcom,qseecom";
		reg = <0x86600000 0x2200000>;
		reg-names = "secapp-region";
		memory-region = <&qseecom_region>;
		qcom,no-clock-support;
		qcom,appsbl-qseecom-support;
		qcom,commonlib64-loaded-by-uefi;
		qcom,qsee-reentrancy-support = <2>;
	};

};

&{/soc@0/imem@146bf000} {
	compatible = "syscon", "simple-mfd";

	reboot-mode {
		compatible = "syscon-reboot-mode";
		offset = <0x65c>;
		mode-normal = <0x77665501>;
		mode-bootloader = <0x77665500>;
		mode-recovery = <0x77665502>;
	};
};
